# STM32H743 register map
File version: 2.4
CPU: CM7 r0p1, little endian, MPU, FPU, 4 interrupt priority bits
Registers are 32-bit, read-write, reset 0x0 unless marked. A register's access mark holds for its fields unless they carry their own. Offsets are from the block's base; [hi:lo] are bit positions.

## ADC3_Common — 模数转换器
Base 0x58026300
Same registers: ADC12_Common 0x40022300
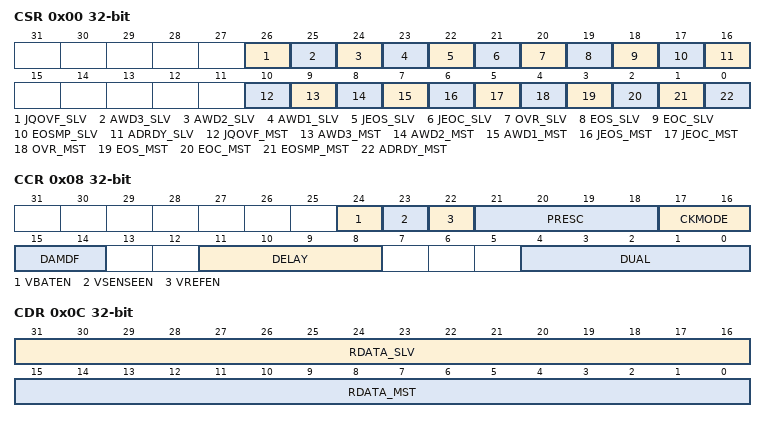
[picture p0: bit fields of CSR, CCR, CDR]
0x00 CSR ro — ADC 通用状态寄存器
  [26] JQOVF_SLV — 从 ADC 注入上下文队列溢出标志
  [25] AWD3_SLV — 从 ADC 模拟看门狗 3 标志
  [24] AWD2_SLV — 从 ADC 模拟看门狗 2 标志
  [23] AWD1_SLV — 从 ADC 模拟看门狗 1 标志
  [22] JEOS_SLV — 从 ADC 注入序列结束标志
  [21] JEOC_SLV — 从 ADC 注入转换结束标志
  [20] OVR_SLV — 从 ADC 溢出标志
  [19] EOS_SLV — 从 ADC 规则序列结束标志
  [18] EOC_SLV — 从 ADC 规则转换结束标志
  [17] EOSMP_SLV — 从 ADC 采样阶段结束标志
  [16] ADRDY_SLV — 从 ADC 就绪
  [10] JQOVF_MST — 主 ADC 注入上下文队列溢出标志
  [9] AWD3_MST — 主 ADC 模拟看门狗 3 标志
  [8] AWD2_MST — 主 ADC 模拟看门狗 2 标志
  [7] AWD1_MST — 主 ADC 模拟看门狗 1 标志
  [6] JEOS_MST — 主 ADC 注入序列结束标志
  [5] JEOC_MST — 主 ADC 注入转换结束标志
  [4] OVR_MST — 主 ADC 溢出标志
  [3] EOS_MST — 主 ADC 规则序列结束标志
  [2] EOC_MST — 主 ADC 规则转换结束标志
  [1] EOSMP_MST — 主 ADC 采样阶段结束标志
  [0] ADRDY_MST — 主 ADC 就绪
0x08 CCR — ADC 通用控制寄存器
  [24] VBATEN — VBAT 使能
  [23] VSENSEEN — 温度传感器使能
  [22] VREFEN — VREFINT 使能
  [21:18] PRESC — ADC 预分频器
  [17:16] CKMODE — ADC 时钟模式
  [15:14] DAMDF — 双 ADC 模式数据格式
  [11:8] DELAY — 两次采样之间的延时
  [4:0] DUAL — 双 ADC 模式选择
0x0C CDR ro — ADC 通用规则数据寄存器（双/三 ADC 模式）
  [31:16] RDATA_SLV — 从 ADC 规则数据
  [15:0] RDATA_MST — 主 ADC 规则数据
0x10 CDR2 ro — ADC x 通用规则数据寄存器（32 位双 ADC 模式）
  [31:0] RDATA_ALT — 主/从交替 ADC 规则数据

## CRC — CRC 校验计算单元
Base 0x58024C00
0x00 DR reset 0xFFFFFFFF — 数据寄存器
0x04 IDR — 独立数据寄存器
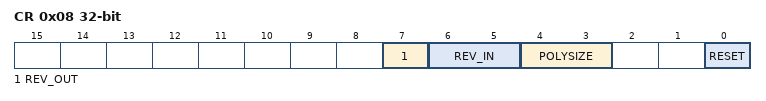
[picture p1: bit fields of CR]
0x08 CR access per field — 控制寄存器
  [7] REV_OUT rw — 输出数据反转
  [6:5] REV_IN rw — 输入数据反转
  [4:3] POLYSIZE rw — 多项式长度
  [0] RESET wo — 复位位
0x10 INIT reset 0xFFFFFFFF — CRC 初始值
  [31:0] CRC_INIT — 可编程 CRC 初始值
0x14 POL reset 0x4C11DB7 — CRC 多项式
  [31:0] POL — 可编程多项式

## LPTIM1 — 低功耗定时器
Base 0x40002400
Same registers: LPTIM2 0x58002400
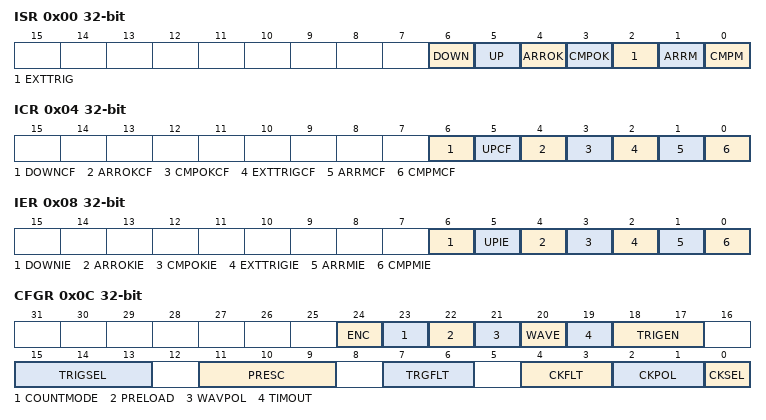
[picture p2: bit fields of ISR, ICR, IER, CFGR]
0x00 ISR ro — 中断与状态寄存器
  [6] DOWN — 计数器方向由增变减
  [5] UP — 计数器方向由减变增
  [4] ARROK — 自动重载寄存器更新完成
  [3] CMPOK — 比较寄存器更新完成
  [2] EXTTRIG — 外部触发边沿事件
  [1] ARRM — 自动重载匹配
  [0] CMPM — 比较匹配
0x04 ICR wo — 中断清除寄存器
  [6] DOWNCF — 方向由增变减清除标志
  [5] UPCF — 方向由减变增清除标志
  [4] ARROKCF — 自动重载寄存器更新完成清除标志
  [3] CMPOKCF — 比较寄存器更新完成清除标志
  [2] EXTTRIGCF — 外部触发有效边沿清除标志
  [1] ARRMCF — 自动重载匹配清除标志
  [0] CMPMCF — 比较匹配清除标志
0x08 IER — 中断使能寄存器
  [6] DOWNIE — 方向由增变减中断使能
  [5] UPIE — 方向由减变增中断使能
  [4] ARROKIE — 自动重载寄存器更新完成中断使能
  [3] CMPOKIE — 比较寄存器更新完成中断使能
  [2] EXTTRIGIE — 外部触发有效边沿中断使能
  [1] ARRMIE — 自动重载匹配中断使能
  [0] CMPMIE — 比较匹配中断使能
0x0C CFGR — 配置寄存器
  [24] ENC — 编码器模式使能
  [23] COUNTMODE — 计数器模式使能
  [22] PRELOAD — 寄存器更新模式
  [21] WAVPOL — 波形极性
  [20] WAVE — 波形形状
  [19] TIMOUT — 超时使能
  [18:17] TRIGEN — 触发使能与极性
  [15:13] TRIGSEL — 触发源选择
  [11:9] PRESC — 时钟预分频器
  [7:6] TRGFLT — 触发信号可配置数字滤波器
  [4:3] CKFLT — 外部时钟可配置数字滤波器
  [2:1] CKPOL — 时钟极性
  [0] CKSEL — 时钟源选择
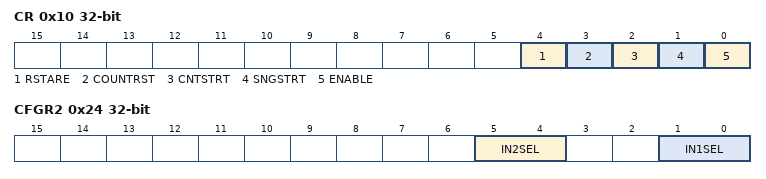
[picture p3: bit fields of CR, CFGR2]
0x10 CR — 控制寄存器
  [4] RSTARE — 计数器读后复位使能
  [3] COUNTRST — 计数器复位
  [2] CNTSTRT — 定时器连续模式启动
  [1] SNGSTRT — LPTIM 单次模式启动
  [0] ENABLE — LPTIM 使能
0x14 CMP — 比较寄存器
  [15:0] CMP — 比较值
0x18 ARR reset 0x1 — 自动重载寄存器
  [15:0] ARR — 自动重载值
0x1C CNT ro — 计数器寄存器
  [15:0] CNT — 计数器值
0x24 CFGR2 — LPTIM 配置寄存器 2
  [5:4] IN2SEL — LPTIM 输入 2 选择
  [1:0] IN1SEL — LPTIM 输入 1 选择

## LPTIM3 — 低功耗定时器
Base 0x58002800
Same registers: LPTIM4 0x58002C00, LPTIM5 0x58003000
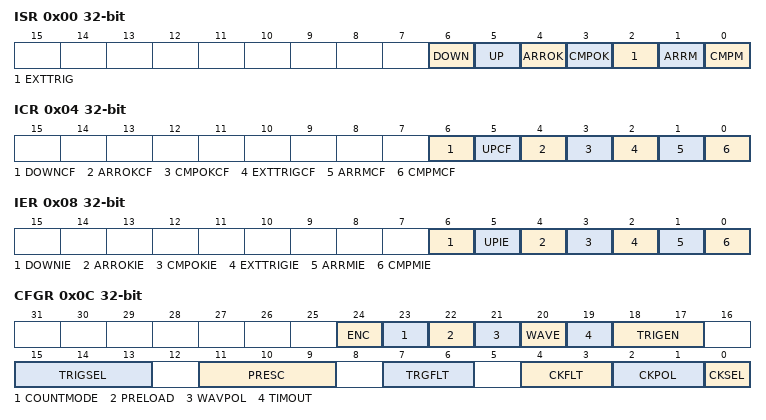
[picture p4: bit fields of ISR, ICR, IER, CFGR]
0x00 ISR ro — 中断与状态寄存器
  [6] DOWN — 计数器方向由上变下
  [5] UP — 计数器方向由下变上
  [4] ARROK — 自动重载寄存器更新完成
  [3] CMPOK — 比较寄存器更新完成
  [2] EXTTRIG — 外部触发边沿事件
  [1] ARRM — 自动重载匹配
  [0] CMPM — 比较匹配
0x04 ICR wo — 中断清零寄存器
  [6] DOWNCF — 方向变下清零标志
  [5] UPCF — 方向变上清零标志
  [4] ARROKCF — 自动重载寄存器更新完成清零标志
  [3] CMPOKCF — 比较寄存器更新完成清零标志
  [2] EXTTRIGCF — 外部触发有效边沿清零标志
  [1] ARRMCF — 自动重载匹配清零标志
  [0] CMPMCF — 比较匹配清零标志
0x08 IER — 中断使能寄存器
  [6] DOWNIE — 方向变下中断使能
  [5] UPIE — 方向变上中断使能
  [4] ARROKIE — 自动重载寄存器更新完成中断使能
  [3] CMPOKIE — 比较寄存器更新完成中断使能
  [2] EXTTRIGIE — 外部触发有效边沿中断使能
  [1] ARRMIE — 自动重载匹配中断使能
  [0] CMPMIE — 比较匹配中断使能
0x0C CFGR — 配置寄存器
  [24] ENC — 编码器模式使能
  [23] COUNTMODE — 计数器模式使能
  [22] PRELOAD — 寄存器更新模式
  [21] WAVPOL — 波形极性
  [20] WAVE — 波形
  [19] TIMOUT — 超时使能
  [18:17] TRIGEN — 触发使能与极性
  [15:13] TRIGSEL — 触发源选择
  [11:9] PRESC — 时钟预分频器
  [7:6] TRGFLT — 触发信号可配置数字滤波器
  [4:3] CKFLT — 外部时钟可配置数字滤波器
  [2:1] CKPOL — 时钟极性
  [0] CKSEL — 时钟源选择
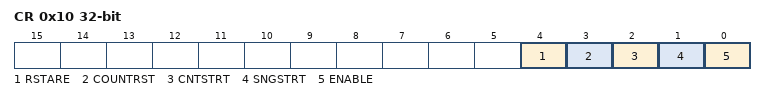
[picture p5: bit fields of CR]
0x10 CR — 控制寄存器
  [4] RSTARE — 读后复位使能
  [3] COUNTRST — 计数器复位
  [2] CNTSTRT — 定时器连续模式启动
  [1] SNGSTRT — LPTIM 单次模式启动
  [0] ENABLE — LPTIM 使能
0x14 CMP — 比较寄存器
  [15:0] CMP — 比较值
0x18 ARR reset 0x1 — 自动重载寄存器
  [15:0] ARR — 自动重载值
0x1C CNT ro — 计数寄存器
  [15:0] CNT — 计数器当前值
0x24 CFGR2 — LPTIM 配置寄存器 2
  [1:0] IN1SEL — LPTIM 输入 1 选择
